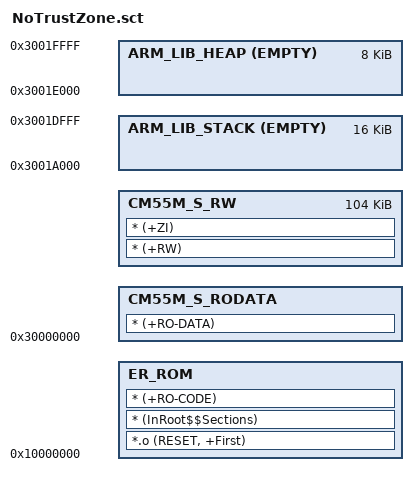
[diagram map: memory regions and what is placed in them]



/*--------------------- Flash Configuration ----------------------------------*/
#define CM55M_ROM_BASE     0x10000000
#define CM55M_ROM_SIZE     0x00020000

/*--------------------- Embedded RAM Configuration ---------------------------*/
#define CM55M_DATA_BASE     0x30000000
#define CM55M_DATA_SIZE     0x00020000

/*--------------------- Stack / Heap Configuration ---------------------------*/
#define __STACK_SIZE    0x00004000
#define __HEAP_SIZE     0x00002000
#define CM55M_APP_DATASECT_SIZE  (CM55M_DATA_SIZE - __STACK_SIZE - __HEAP_SIZE)
#define __STACK_LIMIT   (CM55M_DATA_BASE + CM55M_APP_DATASECT_SIZE)
#define __STACK_BASE    (CM55M_DATA_BASE + CM55M_APP_DATASECT_SIZE + __STACK_SIZE)
#define __HEAP_BASE     (CM55M_DATA_BASE + CM55M_APP_DATASECT_SIZE + __STACK_SIZE)
#define __HEAP_LIMIT    (CM55M_DATA_BASE + CM55M_APP_DATASECT_SIZE + __STACK_SIZE + __HEAP_SIZE)


LR_ROM1 CM55M_ROM_BASE CM55M_ROM_SIZE  {                       
  ER_ROM +0 {                                       
   *.o (RESET, +First)
   * (InRoot$$Sections)
   * (+RO-CODE)
  }
}

LR_ROM2 CM55M_DATA_BASE  CM55M_DATA_SIZE{
  CM55M_S_RODATA  +0 { 
   * (+RO-DATA)
  }	    
  CM55M_S_RW +0 CM55M_APP_DATASECT_SIZE{    
   * (+RW)
   * (+ZI)
  }

  ARM_LIB_STACK __STACK_BASE ALIGN 8 EMPTY -__STACK_SIZE {  
  }
  
  ARM_LIB_HEAP  __HEAP_BASE ALIGN 8 EMPTY __HEAP_SIZE  { 
  }
}
